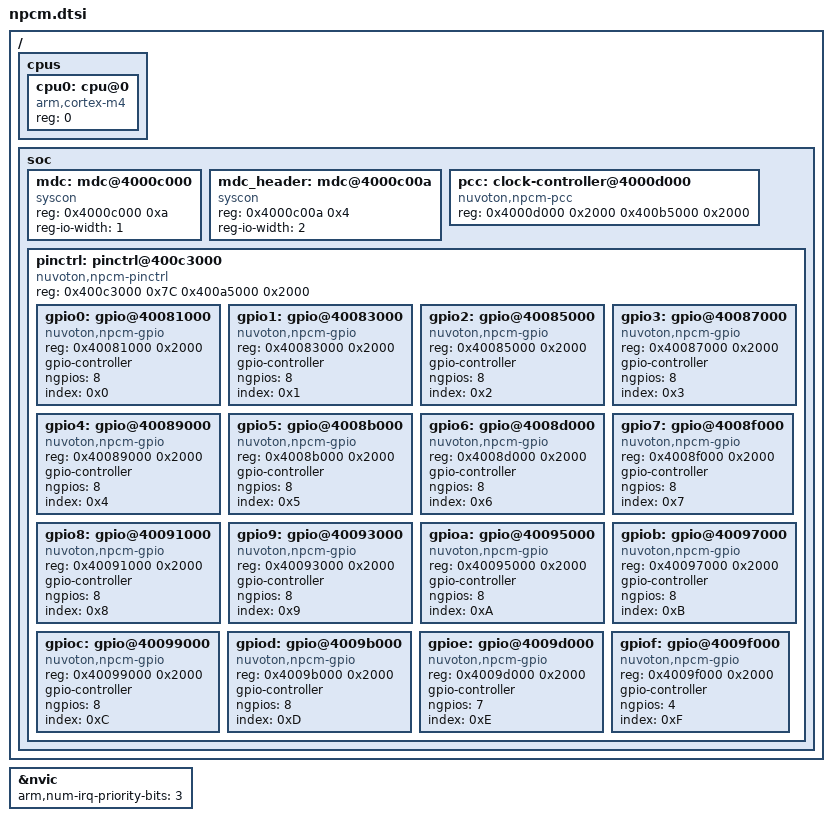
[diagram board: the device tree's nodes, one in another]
/*
 * Copyright (c) 2024 Nuvoton Technology Corporation.
 *
 * SPDX-License-Identifier: Apache-2.0
 */

#include <arm/armv7-m.dtsi>

/* Macros for device tree declarations of npcm soc family */
#include <zephyr/dt-bindings/clock/npcm_clock.h>
#include <zephyr/dt-bindings/pinctrl/npcm-pinctrl.h>
#include <zephyr/dt-bindings/gpio/gpio.h>
#include <freq.h>

/ {
	cpus {
		#address-cells = <1>;
		#size-cells = <0>;

		cpu0: cpu@0 {
			device_type = "cpu";
			compatible = "arm,cortex-m4";
			reg = <0>;
		};
	};

	soc {
		mdc: mdc@4000c000 {
			compatible = "syscon";
			reg = <0x4000c000 0xa>;
			reg-io-width = <1>;
		};

		mdc_header: mdc@4000c00a {
			compatible = "syscon";
			reg = <0x4000c00a 0x4>;
			reg-io-width = <2>;
		};

		pcc: clock-controller@4000d000 {
			compatible = "nuvoton,npcm-pcc";
			/* Cells for clock id */
			#clock-cells = <1>;
			/* First reg region is Power Management Controller */
			/* Second reg region is Core Domain Clock Generator */
			reg = <0x4000d000 0x2000
				   0x400b5000 0x2000>;
			reg-names = "pmc", "cdcg";
		};

		pinctrl: pinctrl@400c3000 {
			compatible = "nuvoton,npcm-pinctrl";
			/* First reg region is System Configuration Device */
			/* Second reg region is System Glue Device */
			reg = <0x400c3000 0x7C
				   0x400a5000 0x2000>;
			reg-names = "scfg", "glue";
			#address-cells = <1>;
			#size-cells = <1>;

			gpio0: gpio@40081000 {
				compatible = "nuvoton,npcm-gpio";
				reg = <0x40081000 0x2000>;
				gpio-controller;
				ngpios = <8>;
				index = <0x0>;
				#gpio-cells=<2>;
			};

			gpio1: gpio@40083000 {
				compatible = "nuvoton,npcm-gpio";
				reg = <0x40083000 0x2000>;
				gpio-controller;
				ngpios = <8>;
				index = <0x1>;
				#gpio-cells=<2>;
			};

			gpio2: gpio@40085000 {
				compatible = "nuvoton,npcm-gpio";
				reg = <0x40085000 0x2000>;
				gpio-controller;
				ngpios = <8>;
				index = <0x2>;
				#gpio-cells=<2>;
			};

			gpio3: gpio@40087000 {
				compatible = "nuvoton,npcm-gpio";
				reg = <0x40087000 0x2000>;
				gpio-controller;
				ngpios = <8>;
				index = <0x3>;
				#gpio-cells=<2>;
			};

			gpio4: gpio@40089000 {
				compatible = "nuvoton,npcm-gpio";
				reg = <0x40089000 0x2000>;
				gpio-controller;
				ngpios = <8>;
				index = <0x4>;
				#gpio-cells=<2>;
			};

			gpio5: gpio@4008b000 {
				compatible = "nuvoton,npcm-gpio";
				reg = <0x4008b000 0x2000>;
				gpio-controller;
				ngpios = <8>;
				index = <0x5>;
				#gpio-cells=<2>;
			};

			gpio6: gpio@4008d000 {
				compatible = "nuvoton,npcm-gpio";
				reg = <0x4008d000 0x2000>;
				gpio-controller;
				ngpios = <8>;
				index = <0x6>;
				#gpio-cells=<2>;
			};

			gpio7: gpio@4008f000 {
				compatible = "nuvoton,npcm-gpio";
				reg = <0x4008f000 0x2000>;
				gpio-controller;
				ngpios = <8>;
				index = <0x7>;
				#gpio-cells=<2>;
			};

			gpio8: gpio@40091000 {
				compatible = "nuvoton,npcm-gpio";
				reg = <0x40091000 0x2000>;
				gpio-controller;
				ngpios = <8>;
				index = <0x8>;
				#gpio-cells=<2>;
			};

			gpio9: gpio@40093000 {
				compatible = "nuvoton,npcm-gpio";
				reg = <0x40093000 0x2000>;
				gpio-controller;
				ngpios = <8>;
				index = <0x9>;
				#gpio-cells=<2>;
			};

			gpioa: gpio@40095000 {
				compatible = "nuvoton,npcm-gpio";
				reg = <0x40095000 0x2000>;
				gpio-controller;
				ngpios = <8>;
				index = <0xA>;
				#gpio-cells=<2>;
			};

			gpiob: gpio@40097000 {
				compatible = "nuvoton,npcm-gpio";
				reg = <0x40097000 0x2000>;
				gpio-controller;
				ngpios = <8>;
				index = <0xB>;
				#gpio-cells=<2>;
			};

			gpioc: gpio@40099000 {
				compatible = "nuvoton,npcm-gpio";
				reg = <0x40099000 0x2000>;
				gpio-controller;
				ngpios = <8>;
				index = <0xC>;
				#gpio-cells=<2>;
			};

			gpiod: gpio@4009b000 {
				compatible = "nuvoton,npcm-gpio";
				reg = <0x4009b000 0x2000>;
				gpio-controller;
				ngpios = <8>;
				index = <0xD>;
				#gpio-cells=<2>;
			};

			gpioe: gpio@4009d000 {
				compatible = "nuvoton,npcm-gpio";
				reg = <0x4009d000 0x2000>;
				gpio-controller;
				ngpios = <7>;
				index = <0xE>;
				#gpio-cells=<2>;
			};

			gpiof: gpio@4009f000 {
				compatible = "nuvoton,npcm-gpio";
				reg = <0x4009f000 0x2000>;
				gpio-controller;
				ngpios = <4>;
				index = <0xF>;
				#gpio-cells=<2>;
			};
		};
	};
};

&nvic {
	arm,num-irq-priority-bits = <3>;
};
